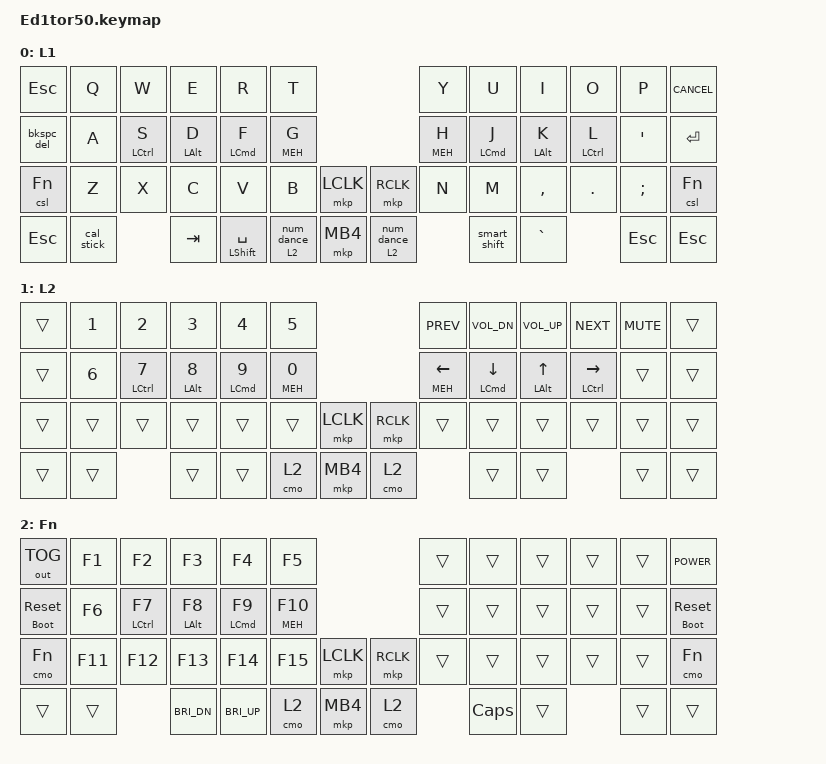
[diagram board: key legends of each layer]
/*
 * Copyright (c) 2020 The ZMK Contributors
 *
 * SPDX-License-Identifier: MIT
 */
// #include "Ed1tor50_drawer/base.dtsi"

// ZMK Core Includes
#include <behaviors.dtsi>
#include <behaviors/num_word.dtsi> // requires https://github.com/urob/zmk-auto-layer module
#include <dt-bindings/zmk/keys.h>
#include <dt-bindings/zmk/bt.h>
#include <dt-bindings/zmk/outputs.h>
#include <dt-bindings/zmk/mouse.h>
#include <dt-bindings/zmk/rgb.h>
#include <dt-bindings/zmk/pointing.h>
#include <dt-bindings/zmk/ext_power.h>

// Temporarily disabled animation includes due to compatibility issues
// #include <behaviors/animation_control.dtsi>
// #include <behaviors/animation_trigger.dtsi>
// #include <dt-bindings/zmk_driver_animation/animation_control.h>
// #include <dt-bindings/zmk_driver_animation/animation_trigger.h>
// #include <dt-bindings/zmk_behavior_default_layer/default_layer.h>


// Layers
#define L1 0
#define L2 1
#define Fn 2

// Meh key
#define MEH LS(LC(LALT))

// Behaviors Constants
#define TAPPING_TERM_MS 280
#define QUICK_TAP_MS 175
#define REQUIRE_PRIOR_IDLE_MS 150

// Combos Constants
#define COMBO_TERM_DEFAULT 30
#define COMBO_QUICK_TAP_MS 100

#define ROTATION0 0.0
#define ROTATION1 22.62
#define ROTATION2 -22.62

// Key positions per hand
#define KEYS_L 0 1 2 3 4 5  12 13 14 15 16 17  24 25 26 27 28 29 30  
#define KEYS_R 6 7 8 9 10 11  18 19 20 21 22 23  31 32 33 34 35 36 37
#define THUMBS   38 39 40 41 42 43  44 45 46 47 48

/* Copied (modified) from https://github.com/caksoylar/zmk-config */
#define COMBO(NAME, BINDINGS, KEYPOS, LAYERS, TERM, QUICKTAP) \
  combo_##NAME { \
    timeout-ms = <TERM>; \
    bindings = <BINDINGS>; \
    key-positions = <KEYPOS>; \
    layers = <LAYERS>; \
    require-prior-idle-ms = <QUICKTAP>; \
  };



// Alpha layer: uncomment desired, comment the others
// #include "L1_colemak-dh.dtsi"
// #include "L1_colemak.dtsi"
// #include "L1_dvorak.dtsi"
// #include "L1_qwerty.dtsi"

// Other layers
// #include "L2.dtsi"
// #include "Fn.dtsi"

// #include "Ed1tor50_drawer/behaviors.dtsi"
// #include "Ed1tor50_drawer/macros.dtsi"
// #include "Ed1tor50_drawer/combos.dtsi"

// ZMK Behaviors Configuration
&mt {
  flavor = "balanced";
  tapping-term-ms = <TAPPING_TERM_MS>;
  quick-tap-ms = <QUICK_TAP_MS>;
  require-prior-idle-ms = <REQUIRE_PRIOR_IDLE_MS>;
};

&lt {
  flavor = "balanced";
  tapping-term-ms = <TAPPING_TERM_MS>;
  quick-tap-ms = <QUICK_TAP_MS>;
  require-prior-idle-ms = <REQUIRE_PRIOR_IDLE_MS>;
};

&sk {
  quick-release;
};

// From: https://github.com/urob/zmk-config/
// num-word, requires PR https://github.com/zmkfirmware/zmk/pull/1451
// Adds arrows and shift to smart layer for more comfortable navigation/selection moves
&num_word {
  continue-list = <BSPC DEL DOT COMMA PLUS MINUS STAR FSLH EQUAL RSHFT LEFT RIGHT UP DOWN>;
};

/ {
  behaviors {
    /*
    Home Row Mods

    - tap: &kp <PARAM_2>
    - hold: &kp <PARAM_1>

    Example: &hrml LCMD T
    */
    /omit-if-no-ref/ hrml: hrm_left {
      bindings = <&kp>, <&kp>;
      compatible = "zmk,behavior-hold-tap";
      flavor = "balanced";
      hold-trigger-key-positions = <KEYS_R THUMBS>;
      hold-trigger-on-release;
      tapping-term-ms = <TAPPING_TERM_MS>;
      quick-tap-ms = <QUICK_TAP_MS>;
      require-prior-idle-ms = <REQUIRE_PRIOR_IDLE_MS>;
      #binding-cells = <2>;
    };

    /omit-if-no-ref/ hrmr: hrm_right {
      bindings = <&kp>, <&kp>;
      compatible = "zmk,behavior-hold-tap";
      flavor = "balanced";
      hold-trigger-key-positions = <KEYS_L THUMBS>;
      hold-trigger-on-release;
      tapping-term-ms = <TAPPING_TERM_MS>;
      quick-tap-ms = <QUICK_TAP_MS>;
      require-prior-idle-ms = <REQUIRE_PRIOR_IDLE_MS>;
      #binding-cells = <2>;
    };

    /*
    - tap: sticky shift
    - double-tap: caps-word (shift + tap mod-morph)
    - hold: shift

    From: https://github.com/urob/zmk-config/
    */
    /omit-if-no-ref/ smart_shift: smart_shift {
      compatible = "zmk,behavior-mod-morph";
      bindings = <&sk RSHFT>, <&caps_word>;
      mods = <(MOD_RSFT)>;
      #binding-cells = <0>;
    };


    /*
    - tap: num-word
    - hold: &mo layer

    From: https://github.com/urob/zmk-config/
    */
    /omit-if-no-ref/ smart_num: smart_num {
      compatible = "zmk,behavior-hold-tap";
      flavor = "balanced";
      tapping-term-ms = <TAPPING_TERM_MS>;
      bindings = <&mo>, <&num_dance>;
      #binding-cells = <2>;
    };

    /*
    - tap: &sl L2
    - tap x 2: &num_word

    From: https://github.com/urob/zmk-config/
    */
    /omit-if-no-ref/ num_dance: num_dance {
      compatible = "zmk,behavior-tap-dance";
      tapping-term-ms = <TAPPING_TERM_MS>;
      bindings = <&sl L2>, <&num_word L2>;
      #binding-cells = <0>;
    };

    /*
    - tap: backspace
    - hold: repeat backspace
    - shift + tap: delete
    - shift + hold: repeat delete

    From: https://zmk.dev/docs/behaviors/mod-morph#advanced-configuration
    */
    /omit-if-no-ref/ bkspc_del: backspace_delete {
      compatible = "zmk,behavior-mod-morph";
      bindings = <&kp BACKSPACE>, <&kp DELETE>;
      mods = <(MOD_LSFT|MOD_RSFT)>;
      #binding-cells = <0>;
    };

    /*
    - tap: reset keyboard
    - hold: enter bootloader mode
    */
    /omit-if-no-ref/ rst_boot: rst_boot {
        compatible = "zmk,behavior-hold-tap";
        #binding-cells = <2>;
        tapping-term-ms = <500>;
        flavor = "tap-preferred";
        bindings = <&bootloader>, <&sys_reset>;
    };

    /*
    - tap: calibrate analog input device
    - parameter: device index (0=first device, 255=all devices)
    */
     /omit-if-no-ref/ cal_stick: calibrate_analog_stick {
         compatible = "zmk,behavior-analog-calibrate";
         #binding-cells = <0>;
     };
  };
};



/ {
  combos {
    compatible = "zmk,combos";
    /*
      KEY POSITIONS
      ╭────────────────────────╮  ╭────────────────────────╮
      │ 0   1   2   3   4   5  │  │ 6   7   8   9   10  11 │
      │ 12  13  14  15  16  17 │  │ 18  19  20  21  22  23 │
      │ 24  25  26  27  28  29 │  │ 30  31  32  33  34  35 │
      ╰───────────╮ 36  37  38 │  │ 39  40  41 ╭───────────╯
                  ╰────────────╯  ╰────────────╯
    */

    /* Symbols */
    // Left
    COMBO(excl, &kp EXCL, 1 13, L1 L2, COMBO_TERM_DEFAULT, COMBO_QUICK_TAP_MS)
    COMBO(at, &kp AT, 2 14, L1 L2, COMBO_TERM_DEFAULT, COMBO_QUICK_TAP_MS)
    COMBO(hash, &kp HASH, 3 15, L1 L2, COMBO_TERM_DEFAULT, COMBO_QUICK_TAP_MS)
    COMBO(dollar, &kp DOLLAR, 4 16, L1 L2, COMBO_TERM_DEFAULT, COMBO_QUICK_TAP_MS)
    COMBO(percent, &kp PERCENT, 5 17, L1 L2, COMBO_TERM_DEFAULT, COMBO_QUICK_TAP_MS)
    COMBO(caret, &kp CARET, 13 25, L1 L2, COMBO_TERM_DEFAULT, COMBO_QUICK_TAP_MS)
    COMBO(ampersand, &kp AMPERSAND, 14 26, L1 L2, COMBO_TERM_DEFAULT, COMBO_QUICK_TAP_MS)
    COMBO(star, &kp STAR, 15 27, L1 L2, COMBO_TERM_DEFAULT, COMBO_QUICK_TAP_MS)
    COMBO(lpar, &kp LPAR, 16 28, L1 L2, COMBO_TERM_DEFAULT, COMBO_QUICK_TAP_MS)
    COMBO(rpar, &kp RPAR, 17 29, L1 L2, COMBO_TERM_DEFAULT, COMBO_QUICK_TAP_MS)

    // Right
    COMBO(minus, &kp MINUS, 7 19, L1 L2 Fn, COMBO_TERM_DEFAULT, COMBO_QUICK_TAP_MS)
    COMBO(equal, &kp EQUAL, 8 20, L1 L2 Fn, COMBO_TERM_DEFAULT, COMBO_QUICK_TAP_MS)
    COMBO(slash, &kp SLASH, 9 21, L1 L2 Fn, COMBO_TERM_DEFAULT, COMBO_QUICK_TAP_MS)
    COMBO(pgup, &kp PG_UP, 6 18, L1 L2 Fn, COMBO_TERM_DEFAULT, COMBO_QUICK_TAP_MS)
    COMBO(pgdn, &kp PG_DN, 18 32, L1 L2 Fn, COMBO_TERM_DEFAULT, COMBO_QUICK_TAP_MS)
    COMBO(lbkt, &kp LBKT, 19 33, L1 L2 Fn, COMBO_TERM_DEFAULT, COMBO_QUICK_TAP_MS)
    COMBO(rbkt, &kp RBKT, 20 34, L1 L2 Fn, COMBO_TERM_DEFAULT, COMBO_QUICK_TAP_MS)
    COMBO(backslash, &kp BACKSLASH, 21 35, L1 L2 Fn, COMBO_TERM_DEFAULT, COMBO_QUICK_TAP_MS)

    /* Bluetooth */
    COMBO(bt_clear, &bt BT_CLR, 1 2 3 4, Fn, COMBO_TERM_DEFAULT, COMBO_QUICK_TAP_MS)
    COMBO(bt_sel_0, &bt BT_SEL 0, 1 13, Fn, COMBO_TERM_DEFAULT, COMBO_QUICK_TAP_MS)
    COMBO(bt_sel_1, &bt BT_SEL 1, 2 14, Fn, COMBO_TERM_DEFAULT, COMBO_QUICK_TAP_MS)
    COMBO(bt_sel_2, &bt BT_SEL 2, 3 15, Fn, COMBO_TERM_DEFAULT, COMBO_QUICK_TAP_MS)
    COMBO(bt_sel_3, &bt BT_SEL 3, 4 16, Fn, COMBO_TERM_DEFAULT, COMBO_QUICK_TAP_MS)
    COMBO(bt_sel_4, &bt BT_SEL 4, 5 17, Fn, COMBO_TERM_DEFAULT, COMBO_QUICK_TAP_MS)

    /* Media */
    COMBO(play, &kp C_PP, 6 7, L1 L2 Fn, COMBO_TERM_DEFAULT, COMBO_QUICK_TAP_MS)

    /* Analog Input Calibration */
    /* COMBO(calibrate_stick, &cal_stick 0, 25 26 27, Fn, COMBO_TERM_DEFAULT, COMBO_QUICK_TAP_MS) */
  };
};

/ {
  macros {
    /*
      Temporarily switches to a layer (&mo) while a modifier is held. This is
      an implementation of QMK's `LM()` using ZMK's parameterized macros.

      Params:
        1. Layer to switch to
        2. Modifier to press while layer is active

      Example:
        `&lm L1 LSHIFT`
     */
    /omit-if-no-ref/ lm: lm {
      wait-ms = <0>;
      tap-ms = <0>;
      compatible = "zmk,behavior-macro-two-param";
      #binding-cells = <2>;
      bindings = <&macro_param_1to1>,
        <&macro_press &mo MACRO_PLACEHOLDER>,
        <&macro_param_2to1>,
        <&macro_press &kp MACRO_PLACEHOLDER>,
        <&macro_pause_for_release>,
        <&macro_param_2to1>,
        <&macro_release &kp MACRO_PLACEHOLDER>,
        <&macro_param_1to1>,
        <&macro_release &mo MACRO_PLACEHOLDER>;
    };

    /*
      Practically identical to &sl, except it triggers a `K_CANCEL` right before to clear
      any active smart layers. This prevents nested/stacked layer activation when needed.

      Params:
        1. Layer to switch to

      Example:
        `&csl L1`
     */
    /omit-if-no-ref/ csl: clear_sl {
      wait-ms = <0>;
      tap-ms = <0>;
      compatible = "zmk,behavior-macro-one-param";
      #binding-cells = <1>;
      bindings = <&macro_tap &kp K_CANCEL>,
        <&macro_param_1to1>,
        <&macro_press &sl MACRO_PLACEHOLDER>,
        <&macro_pause_for_release>,
        <&macro_param_1to1>,
        <&macro_release &sl MACRO_PLACEHOLDER>;
    };

    /*
      Practically identical to &mo, except it triggers a `K_CANCEL` right before to clear
      any active smart layers. This prevents nested/stacked layer activation when needed.
      It's also useful to maintain more consistent expectations when holding a cancel/exit layer
      key from a smart layer.

      Params:
        1. Layer to switch to

      Example:
        `&cmo L1`
     */
    /omit-if-no-ref/ cmo: clear_mo {
      wait-ms = <0>;
      tap-ms = <0>;
      compatible = "zmk,behavior-macro-one-param";
      #binding-cells = <1>;
      bindings = <&macro_tap &kp K_CANCEL>,
        <&macro_param_1to1>,
        <&macro_press &mo MACRO_PLACEHOLDER>,
        <&macro_pause_for_release>,
        <&macro_param_1to1>,
        <&macro_release &mo MACRO_PLACEHOLDER>;
    };



    }; 

}; 


/ {
    volknob: volume_encoder {
            compatible = "zmk,behavior-sensor-rotate";
            #sensor-binding-cells = <0>;
            bindings = <&kp C_VOL_DN>, <&kp C_VOL_UP>;
        };

    rgb_encoder: rgb_encoder {
        compatible = "zmk,behavior-sensor-rotate";
        #sensor-binding-cells = <0>;
        bindings = <&rgb_ug RGB_BRI>, <&rgb_ug RGB_BRD>;
    };

    scroll_encoder: scroll_encoder {
        compatible = "zmk,behavior-sensor-rotate";
        #sensor-binding-cells = <0>;
        bindings = <&msc SCRL_DOWN>, <&msc SCRL_UP>;

        tap-ms = <100>;
    };
};

/ {
  keymap {
    compatible = "zmk,keymap";

    qwerty_layer {
      display-name = "L1";
      bindings = <

/**
// ╭───────────────┬───────────────┬───────────────┬───────────────┬───────────────┬───────────────╮                                   ╭───────────────┬───────────────┬───────────────┬───────────────┬───────────────┬───────────────╮
// │0              │1              │2              │3              │4              │5              │                                   │6              │7              │8              │9              │10             │11             │*/
    &kp ESC         &kp Q           &kp W           &kp E           &kp R           &kp T                                               &kp Y           &kp U           &kp I           &kp O           &kp P           &kp K_CANCEL
/**
// ├───────────────├───────────────┼───────────────┼───────────────┼───────────────┼───────────────┤                                   ├───────────────├───────────────┼───────────────┼───────────────┼───────────────┼───────────────┤
// │12             │13             │14             │15             │16             │17             │                                   │18             │19             │20             │21             │22             │23             │*/
    &bkspc_del      &kp A           &hrml LCTRL S   &hrml LALT D    &hrml LCMD F    &hrml MEH G                                         &hrmr MEH H     &hrmr LCMD J    &hrmr LALT K    &hrmr LCTRL L   &kp SQT         &kp ENTER

/**
// ├───────────────├───────────────┼───────────────┼───────────────┼───────────────┼───────────────┤                                   ├───────────────├───────────────┼───────────────┼───────────────┼───────────────┼───────────────┤
// │24             │25             │26             │27             │28             │29             │                                   │30             │31             │32             │33             │34             │35             │*/
    &csl Fn         &kp Z           &kp X           &kp C           &kp V           &kp B           &mkp LCLK                &mkp RCLK  &kp N           &kp M           &kp COMMA       &kp DOT         &kp SEMICOLON   &csl Fn

/**
// ╰───────────────┴───────────────┴───────────────┼───────────────┼───────────────┼───────────────┤                                   ├───────────────├───────────────┼───────────────┼───────────────┴───────────────┴───────────────╯
//                                                 │36             │37             │38             │                                   │39             │40             │41             │*/
    &kp ESC         &cal_stick                &kp TAB         &mt LSHFT SPACE &smart_num L2 0              &mkp MB4               &smart_num L2 0 &smart_shift    &kp GRAVE                       &kp ESC          &kp ESC

/**
//                                                 ╰───────────────┴───────────────┴───────────────╯                                   ╰───────────────┴───────────────┴───────────────╯*/
      >;
      sensor-bindings = <&rgb_encoder>, <&volknob>;
    };

    layer_2 {
      display-name = "L2";
      bindings = <
// ╭───────────────┬───────────────┬───────────────┬───────────────┬───────────────┬───────────────╮                                   ╭───────────────┬───────────────┬───────────────┬───────────────┬───────────────┬───────────────╮
// │0              │1              │2              │3              │4              │5              │                                   │6              │7              │8              │9              │10             │11             │
    &trans          &kp N1          &kp N2          &kp N3          &kp N4          &kp N5                                              &kp C_PREV      &kp C_VOL_DN    &kp C_VOL_UP    &kp C_NEXT      &kp C_MUTE      &trans
// ├───────────────├───────────────┼───────────────┼───────────────┼───────────────┼───────────────┤                                   ├───────────────├───────────────┼───────────────┼───────────────┼───────────────┼───────────────┤
// │12             │13             │14             │15             │16             │17             │                                   │18             │19             │20             │21             │22             │23             │
    &trans          &kp N6          &hrml LCTRL N7  &hrml LALT N8   &hrml LCMD N9   &hrml MEH N0                                        &hrmr MEH LEFT  &hrmr LCMD DOWN &hrmr LALT UP   &hrmr LCTRL RIGHT&trans         &trans
// ├───────────────├───────────────┼───────────────┼───────────────┼───────────────┼───────────────┤                                   ├───────────────├───────────────┼───────────────┼───────────────┼───────────────┼───────────────┤
// │24             │25             │26             │27             │28             │29             │                                   │30             │31             │32             │33             │34             │35             │
    &trans          &trans          &trans          &trans          &trans          &trans          &mkp LCLK                &mkp RCLK  &trans          &trans          &trans          &trans          &trans          &trans
// ╰───────────────┴───────────────┴───────────────┼───────────────┼───────────────┼───────────────┤                                   ├───────────────├───────────────┼───────────────┼───────────────┴───────────────┴───────────────╯
//                                                 │36             │37             │38             │                                   │39             │40             │41             │
    &trans          &trans                          &trans          &trans          &cmo L2                      &mkp MB4               &cmo L2         &trans          &trans                          &trans          &trans
//                                                 ╰───────────────┴───────────────┴───────────────╯                                   ╰───────────────┴───────────────┴───────────────╯
      >;
      sensor-bindings = <&rgb_encoder>, <&volknob>;
    };

    fn_layer {
      display-name = "Fn";
      bindings = <
// ╭───────────────┬───────────────┬───────────────┬───────────────┬───────────────┬───────────────╮                                   ╭───────────────┬───────────────┬───────────────┬───────────────┬───────────────┬───────────────╮
// │0              │1              │2              │3              │4              │5              │                                   │6              │7              │8              │9              │10             │11             │
    &out OUT_TOG    &kp F1          &kp F2          &kp F3          &kp F4          &kp F5                                              &trans          &trans          &trans          &trans          &trans          &kp C_POWER
// ├───────────────├───────────────┼───────────────┼───────────────┼───────────────┼───────────────┤                                   ├───────────────├───────────────┼───────────────┼───────────────┼───────────────┼───────────────┤
// │12             │13             │14             │15             │16             │17             │                                   │18             │19             │20             │21             │22             │23             │
    &rst_boot 0 0   &kp F6          &hrml LCTRL F7  &hrml LALT F8   &hrml LCMD F9   &hrml MEH F10                                       &trans          &trans          &trans          &trans          &trans          &rst_boot 0 0
// ├───────────────├───────────────┼───────────────┼───────────────┼───────────────┼───────────────┤                                   ├───────────────├───────────────┼───────────────┼───────────────┼───────────────┼───────────────┤
// │24             │25             │26             │27             │28             │29             │                                   │30             │31             │32             │33             │34             │35             │
    &cmo Fn         &kp F11         &kp F12         &kp F13         &kp F14         &kp F15         &mkp LCLK                &mkp RCLK  &trans          &trans          &trans          &trans          &trans          &cmo Fn
// ╰───────────────┴───────────────┴───────────────┼───────────────┼───────────────┼───────────────┤                                   ├───────────────├───────────────┼───────────────┼───────────────┴───────────────┴───────────────╯
//                                                 │36             │37             │38             │                                   │39             │40             │41             │
    &trans          &trans                          &kp C_BRI_DN    &kp C_BRI_UP    &cmo L2                      &mkp MB4               &cmo L2         &kp CAPSLOCK    &trans                          &trans          &trans
//                                                 ╰───────────────┴───────────────┴───────────────╯                                   ╰───────────────┴───────────────┴───────────────╯
      >;
      sensor-bindings = <&rgb_encoder>, <&volknob>;
    };

  };
};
